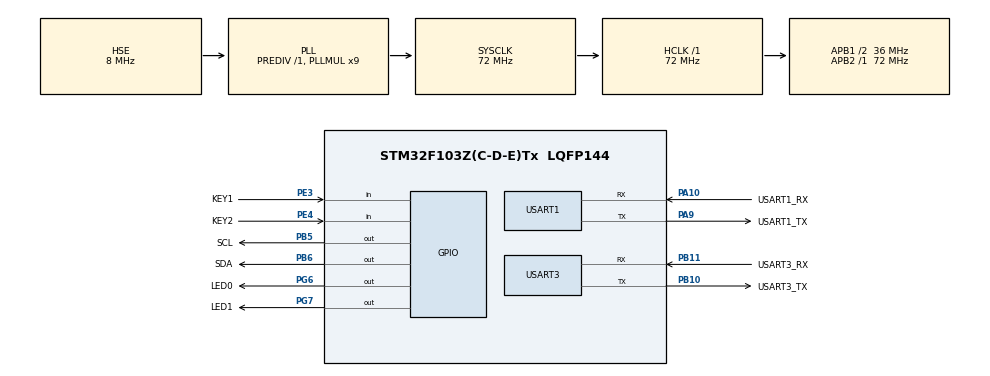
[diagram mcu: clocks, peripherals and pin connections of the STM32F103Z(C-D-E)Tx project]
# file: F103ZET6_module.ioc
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FREERTOS.Queues01=InputEventQueue,10,uint32_t,0,Dynamic,NULL,NULL
FREERTOS.Tasks01=defaultTask,24,128,StartDefaultTask,Default,NULL,Dynamic,NULL,NULL;TaskUserinfo,24,256,TaskPrintfInfo,As external,NULL,Dynamic,NULL,NULL;App,24,256,App_control,As external,NULL,Dynamic,NULL,NULL
FREERTOS.configGENERATE_RUN_TIME_STATS=1
FREERTOS.configTOTAL_HEAP_SIZE=4096
FREERTOS.configUSE_STATS_FORMATTING_FUNCTIONS=1
Mcu.Family=STM32F1
Mcu.Name=STM32F103Z(C-D-E)Tx
Mcu.Package=LQFP144
NVIC.PriorityGroup=NVIC_PRIORITYGROUP_4
NVIC.TIM6_IRQn=true\:1\:0\:true\:false\:true\:false\:true\:true\:true
NVIC.TIM8_UP_IRQn=true\:15\:0\:false\:false\:true\:false\:false\:true\:true
NVIC.TimeBase=TIM8_UP_IRQn
NVIC.TimeBaseIP=TIM8
NVIC.USART3_IRQn=true\:5\:0\:false\:false\:true\:true\:true\:true\:true
OSC_IN.Mode=HSE-External-Oscillator
OSC_IN.Signal=RCC_OSC_IN
OSC_OUT.Mode=HSE-External-Oscillator
OSC_OUT.Signal=RCC_OSC_OUT
PA10.GPIO_Label=USART1_RX
PA10.GPIO_PuPd=GPIO_PULLUP
PA10.Mode=Asynchronous
PA10.Signal=USART1_RX
PA13.Mode=Serial_Wire
PA13.Signal=SYS_JTMS-SWDIO
PA14.Mode=Serial_Wire
PA14.Signal=SYS_JTCK-SWCLK
PA9.GPIO_Label=USART1_TX
PA9.Mode=Asynchronous
PA9.Signal=USART1_TX
PB10.GPIO_Label=USART3_TX
PB10.Mode=Asynchronous
PB10.Signal=USART3_TX
PB11.GPIO_Label=USART3_RX
PB11.Mode=Asynchronous
PB11.Signal=USART3_RX
PB5.GPIO_Label=SCL
PB5.GPIO_ModeDefaultOutputPP=GPIO_MODE_OUTPUT_OD
PB5.GPIO_PuPd=GPIO_NOPULL
PB5.GPIO_Speed=GPIO_SPEED_FREQ_HIGH
PB5.PinState=GPIO_PIN_SET
PB5.Signal=GPIO_Output
PB6.GPIO_Label=SDA
PB6.GPIO_ModeDefaultOutputPP=GPIO_MODE_OUTPUT_OD
PB6.GPIO_PuPd=GPIO_NOPULL
PB6.GPIO_Speed=GPIO_SPEED_FREQ_HIGH
PB6.PinState=GPIO_PIN_SET
PB6.Signal=GPIO_Output
PC14-OSC32_IN.Mode=LSE-External-Oscillator
PC14-OSC32_IN.Signal=RCC_OSC32_IN
PC15-OSC32_OUT.Mode=LSE-External-Oscillator
PC15-OSC32_OUT.Signal=RCC_OSC32_OUT
PE3.GPIO_Label=KEY1
PE3.GPIO_PuPd=GPIO_PULLUP
PE3.Signal=GPIO_Input
PE4.GPIO_Label=KEY2
PE4.GPIO_PuPd=GPIO_PULLUP
PE4.Signal=GPIO_Input
PG6.GPIO_Label=LED0
PG6.GPIO_PuPd=GPIO_PULLUP
PG6.GPIO_Speed=GPIO_SPEED_FREQ_HIGH
PG6.PinState=GPIO_PIN_SET
PG6.Signal=GPIO_Output
PG7.GPIO_Label=LED1
PG7.GPIO_PuPd=GPIO_PULLUP
PG7.GPIO_Speed=GPIO_SPEED_FREQ_HIGH
PG7.PinState=GPIO_PIN_SET
PG7.Signal=GPIO_Output
ProjectManager.HeapSize=0x200
ProjectManager.StackSize=0x400
ProjectManager.TargetToolchain=MDK-ARM V5.32
RCC.AHBFreq_Value=72000000
RCC.APB1CLKDivider=RCC_HCLK_DIV2
RCC.APB1Freq_Value=36000000
RCC.APB1TimFreq_Value=72000000
RCC.APB2Freq_Value=72000000
RCC.APB2TimFreq_Value=72000000
RCC.HCLKFreq_Value=72000000
RCC.PLLMUL=RCC_PLL_MUL9
RCC.PLLSourceVirtual=RCC_PLLSOURCE_HSE
RCC.SYSCLKFreq_VALUE=72000000
RCC.SYSCLKSource=RCC_SYSCLKSOURCE_PLLCLK
RCC.USBFreq_Value=72000000
TIM6.AutoReloadPreload=TIM_AUTORELOAD_PRELOAD_ENABLE
TIM6.Period=3600-1
TIM6.TIM_MasterOutputTrigger=TIM_TRGO_RESET
USART1.VirtualMode=VM_ASYNC
USART3.VirtualMode=VM_ASYNC
VP_FREERTOS_VS_CMSIS_V2.Mode=CMSIS_V2
VP_SYS_VS_tim8.Mode=TIM8
VP_TIM6_VS_ClockSourceINT.Mode=Enable_Timer
board=custom

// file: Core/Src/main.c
/* USER CODE BEGIN Header */
/**
  ******************************************************************************
  * @file           : main.c
  * @brief          : Main program body
  ******************************************************************************
  * @attention
  *
  * Copyright (c) 2024 STMicroelectronics.
  * All rights reserved.
  *
  * This software is licensed under terms that can be found in the LICENSE file
  * in the root directory of this software component.
  * If no LICENSE file comes with this software, it is provided AS-IS.
  *
  ******************************************************************************
  */
/* USER CODE END Header */
#include "main.h"
#include "cmsis_os.h"
#include "tim.h"
#include "usart.h"
#include "gpio.h"

/* USER CODE BEGIN Includes */
#include "driver_USART.h"
#include "driver_Key.h"
#include "App.h"
/* USER CODE END Includes */

void SystemClock_Config(void);
void MX_FREERTOS_Init(void);

int main(void)
{

  /* MCU Configuration--------------------------------------------------------*/

  /* Reset of all peripherals, Initializes the Flash interface and the Systick. */
  HAL_Init();

  /* Configure the system clock */
  SystemClock_Config();

  /* Initialize all configured peripherals */
  MX_GPIO_Init();
  MX_USART1_UART_Init();
  MX_USART3_UART_Init();
  MX_TIM6_Init();
  /* USER CODE BEGIN 2 */
  // EnableDebugIRQ();
  EnableUART3IRQ(); //初始化串口3—网卡接收中断
  Init_Connect_Display();

  /* USER CODE END 2 */

  /* Init scheduler */
  osKernelInitialize();

  /* Call init function for freertos objects (in cmsis_os2.c) */
  MX_FREERTOS_Init();

  /* Start scheduler */
  osKernelStart();

  /* We should never get here as control is now taken by the scheduler */

  /* Infinite loop */
  /* USER CODE BEGIN WHILE */
  // while (1)
  // {

  //   App();

    /* USER CODE END WHILE */

    /* USER CODE BEGIN 3 */

  // }
  /* USER CODE END 3 */
}

void SystemClock_Config(void)
{
  RCC_OscInitTypeDef RCC_OscInitStruct = {0};
  RCC_ClkInitTypeDef RCC_ClkInitStruct = {0};

  /** Initializes the RCC Oscillators according to the specified parameters
  * in the RCC_OscInitTypeDef structure.
  */
  RCC_OscInitStruct.OscillatorType = RCC_OSCILLATORTYPE_HSE;
  RCC_OscInitStruct.HSEState = RCC_HSE_ON;
  RCC_OscInitStruct.HSEPredivValue = RCC_HSE_PREDIV_DIV1;
  RCC_OscInitStruct.HSIState = RCC_HSI_ON;
  RCC_OscInitStruct.PLL.PLLState = RCC_PLL_ON;
  RCC_OscInitStruct.PLL.PLLSource = RCC_PLLSOURCE_HSE;
  RCC_OscInitStruct.PLL.PLLMUL = RCC_PLL_MUL9;
  if (HAL_RCC_OscConfig(&RCC_OscInitStruct) != HAL_OK)
  {
    Error_Handler();
  }

  /** Initializes the CPU, AHB and APB buses clocks
  */
  RCC_ClkInitStruct.ClockType = RCC_CLOCKTYPE_HCLK|RCC_CLOCKTYPE_SYSCLK
                              |RCC_CLOCKTYPE_PCLK1|RCC_CLOCKTYPE_PCLK2;
  RCC_ClkInitStruct.SYSCLKSource = RCC_SYSCLKSOURCE_PLLCLK;
  RCC_ClkInitStruct.AHBCLKDivider = RCC_SYSCLK_DIV1;
  RCC_ClkInitStruct.APB1CLKDivider = RCC_HCLK_DIV2;
  RCC_ClkInitStruct.APB2CLKDivider = RCC_HCLK_DIV1;

  if (HAL_RCC_ClockConfig(&RCC_ClkInitStruct, FLASH_LATENCY_2) != HAL_OK)
  {
    Error_Handler();
  }
}

void HAL_TIM_PeriodElapsedCallback(TIM_HandleTypeDef *htim)
{
  if (htim->Instance == TIM8) {
    HAL_IncTick();
  }
}

void Error_Handler(void)
{
  __disable_irq();
  while (1)
  {
  }
}

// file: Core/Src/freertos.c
/* USER CODE BEGIN Header */
/**
  ******************************************************************************
  * File Name          : freertos.c
  * Description        : Code for freertos applications
  ******************************************************************************
  * @attention
  *
  * Copyright (c) 2024 STMicroelectronics.
  * All rights reserved.
  *
  * This software is licensed under terms that can be found in the LICENSE file
  * in the root directory of this software component.
  * If no LICENSE file comes with this software, it is provided AS-IS.
  *
  ******************************************************************************
  */
/* USER CODE END Header */

#include "FreeRTOS.h"
#include "task.h"
#include "main.h"
#include "cmsis_os.h"
#include "Input_system.h"
/* USER CODE BEGIN Includes */
#include <stdio.h>
/* USER CODE END Includes */

/* USER CODE BEGIN Variables */
extern volatile uint32_t ulHighFrequencyTimerTicks;//计数值
/* USER CODE END Variables */
/* Definitions for defaultTask */
osThreadId_t defaultTaskHandle;
const osThreadAttr_t defaultTask_attributes = {
  .name = "defaultTask",
  .stack_size = 128 * 4,
  .priority = (osPriority_t) osPriorityNormal,
};
/* Definitions for TaskUserinfo */
osThreadId_t TaskUserinfoHandle;
const osThreadAttr_t TaskUserinfo_attributes = {
  .name = "TaskUserinfo",
  .stack_size = 256 * 4,
  .priority = (osPriority_t) osPriorityNormal,
};
/* Definitions for App */
osThreadId_t AppHandle;
const osThreadAttr_t App_attributes = {
  .name = "App",
  .stack_size = 256 * 4,
  .priority = (osPriority_t) osPriorityNormal,
};
/* Definitions for InputEventQueue */
osMessageQueueId_t InputEventQueueHandle;
const osMessageQueueAttr_t InputEventQueue_attributes = {
  .name = "InputEventQueue"
};

void StartDefaultTask(void *argument);
extern void TaskPrintfInfo(void *argument);
extern void App_control(void *argument);

void MX_FREERTOS_Init(void); /* (MISRA C 2004 rule 8.1) */

/* Hook prototypes */
void configureTimerForRunTimeStats(void);
unsigned long getRunTimeCounterValue(void);

/* USER CODE BEGIN 1 */
/* Functions needed when configGENERATE_RUN_TIME_STATS is on */
__weak void configureTimerForRunTimeStats(void)
{
  ulHighFrequencyTimerTicks = 0ul;
}

__weak unsigned long getRunTimeCounterValue(void)
{
  return ulHighFrequencyTimerTicks;
}
/* USER CODE END 1 */

void MX_FREERTOS_Init(void) {

  /* Create the queue(s) */
  /* creation of InputEventQueue */
  InputEventQueueHandle = osMessageQueueNew (10, sizeof(InputEvent), &InputEventQueue_attributes);

  /* USER CODE BEGIN RTOS_QUEUES */
  /* add queues, ... */
  if (NULL != InputEventQueueHandle)
    printf("创建 InputEventQueue 消息队列成功!\r\n");
  /* USER CODE END RTOS_QUEUES */

  /* Create the thread(s) */
  /* creation of defaultTask */
  defaultTaskHandle = osThreadNew(StartDefaultTask, NULL, &defaultTask_attributes);

  /* creation of TaskUserinfo */
  TaskUserinfoHandle = osThreadNew(TaskPrintfInfo, NULL, &TaskUserinfo_attributes);

  /* creation of App */
  AppHandle = osThreadNew(App_control, NULL, &App_attributes);

}

void StartDefaultTask(void *argument)
{
  /* USER CODE BEGIN StartDefaultTask */
	// printf("StartDefaultTask\r\n");
  /* Infinite loop */
  for(;;)
  {
    // printf("StartDefaultTask is running\r\n");
    osDelay(1);
  }
  /* USER CODE END StartDefaultTask */
}
